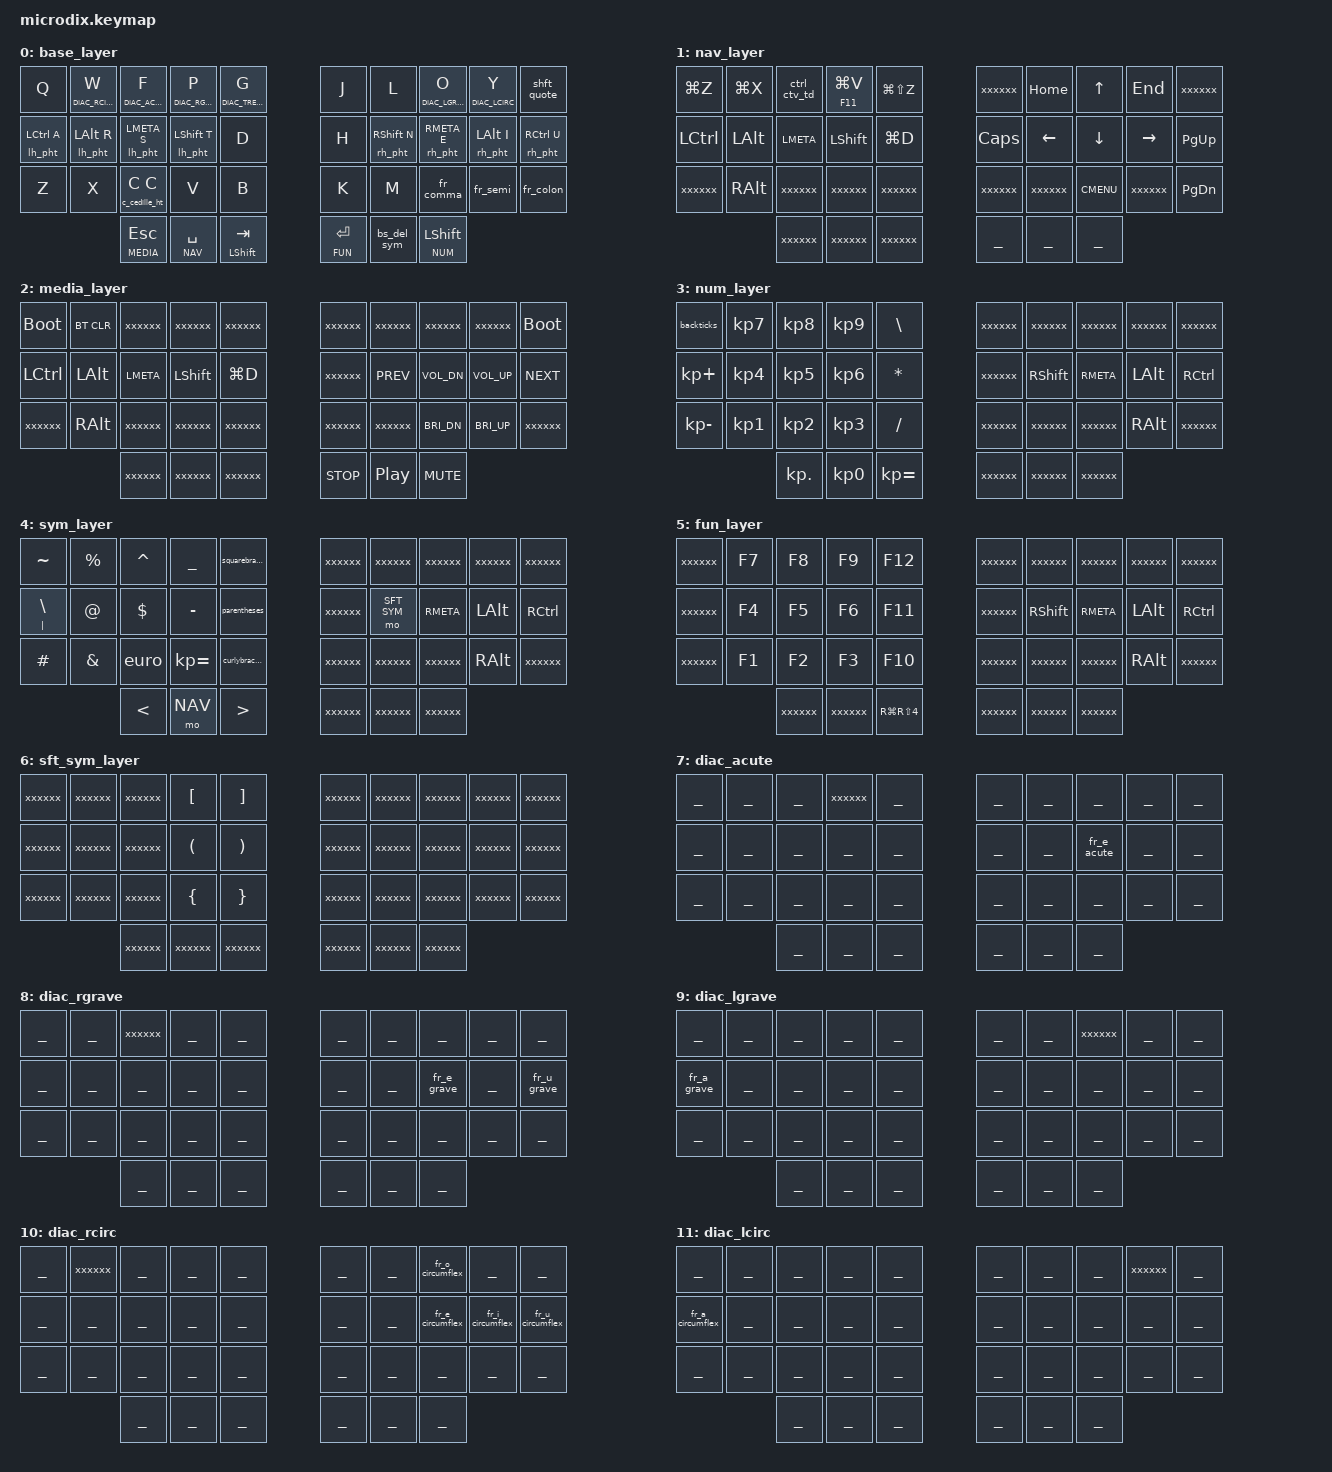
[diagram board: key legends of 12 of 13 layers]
/*
 * Copyright (c) 2020 The ZMK Contributors
 *
 * SPDX-License-Identifier: MIT
 */
#define HOST_OS 2
#include <behaviors.dtsi>
#include <dt-bindings/zmk/keys.h>
#include <dt-bindings/zmk/bt.h>

#include "zmk-helpers/helper.h"
#include "zmk-helpers/key-labels/36.h"
#include "zmk-helpers/unicode-chars/french.dtsi"

#define BASE       0
#define NAV        1
#define MEDIA      2
#define NUM        3
#define SYM        4
#define FUN        5
#define SFT_SYM    6
#define DIAC_ACUTE 7
#define DIAC_RGRAVE 8
#define DIAC_LGRAVE 9
#define DIAC_RCIRC 10
#define DIAC_LCIRC 11
#define DIAC_TREMA 12

#include "include/settings.dtsi"
#include "include/unicode.dtsi"
#include "include/macros.dtsi"
#include "include/combos.dtsi"
#include "include/tap_dance.dtsi"
#include "include/homerow_mod.dtsi"

/* keymap */

ZMK_LAYER(base_layer,
// ╭────────────────────────┬────────────────────────┬────────────────────────┬────────────────────────┬────────────────────────╮    ╭────────────────────────┬────────────────────────┬────────────────────────┬────────────────────────┬────────────────────────╮
    &kp Q                    &lt DIAC_RCIRC W         &lt DIAC_ACUTE F         &lt DIAC_RGRAVE P        &lt DIAC_TREMA G              &kp J                    &kp L                    &lt DIAC_LGRAVE O        &lt DIAC_LCIRC Y         &shft_quote
// ├────────────────────────┼────────────────────────┼────────────────────────┼────────────────────────┼────────────────────────┤    ├────────────────────────┼────────────────────────┼────────────────────────┼────────────────────────┼────────────────────────┤
    &lh_pht LCTRL A          &lh_pht LALT R           &lh_pht LMETA S          &lh_pht LSHFT T          &kp D                         &kp H                    &rh_pht RSHFT N          &rh_pht RMETA E          &rh_pht LALT I           &rh_pht RCTRL U
// ├────────────────────────┼────────────────────────┼────────────────────────┼────────────────────────┼────────────────────────┤    ├────────────────────────┼────────────────────────┼────────────────────────┼────────────────────────┼────────────────────────┤
    &kp Z                    &kp X                    &c_cedille_ht C C        &kp V                    &kp B                         &kp K                    &kp M                    &fr_comma                &fr_semi                 &fr_colon
// ╰────────────────────────┴────────────────────────┴────────────────────────┴────────────────────────┼────────────────────────┤    ├────────────────────────┼────────────────────────┼────────────────────────┼────────────────────────┼────────────────────────╯
                                                      &lt MEDIA ESC            &lt NAV SPACE            &mt LSHFT TAB                 &lt FUN ENTER            &bs_del_sym              &lt NUM LSHFT
//                                                   ╰────────────────────────┴────────────────────────┴────────────────────────╯    ╰────────────────────────┴────────────────────────┴────────────────────────╯
)
ZMK_LAYER(nav_layer,
// ╭────────────────────────┬────────────────────────┬────────────────────────┬────────────────────────┬────────────────────────╮    ╭────────────────────────┬────────────────────────┬────────────────────────┬────────────────────────┬────────────────────────╮
    &kp LG(Z)                &kp LG(X)                &ctrl_ctv_td             &mt F11 LG(V)            &kp LG(LS(Z))                 xxxxxx                   &kp HOME                 &kp UP_ARROW             &kp END                  xxxxxx
// ├────────────────────────┼────────────────────────┼────────────────────────┼────────────────────────┼────────────────────────┤    ├────────────────────────┼────────────────────────┼────────────────────────┼────────────────────────┼────────────────────────┤
    &kp LCTRL                &kp LALT                 &kp LMETA                &kp LSHFT                &kp LG(D)                     &kp CAPSLOCK             &kp LEFT_ARROW           &kp DOWN_ARROW           &kp RIGHT_ARROW          &kp PG_UP
// ├────────────────────────┼────────────────────────┼────────────────────────┼────────────────────────┼────────────────────────┤    ├────────────────────────┼────────────────────────┼────────────────────────┼────────────────────────┼────────────────────────┤
    xxxxxx                   &kp RALT                 xxxxxx                   xxxxxx                   xxxxxx                        xxxxxx                   xxxxxx                   &kp K_CMENU              xxxxxx                   &kp PG_DN
// ╰────────────────────────┴────────────────────────┴────────────────────────┴────────────────────────┼────────────────────────┤    ├────────────────────────┼────────────────────────┼────────────────────────┼────────────────────────┼────────────────────────╯
                                                      xxxxxx                   xxxxxx                   xxxxxx                        ______                   ______                   ______
//                                                   ╰────────────────────────┴────────────────────────┴────────────────────────╯    ╰────────────────────────┴────────────────────────┴────────────────────────╯
)
ZMK_LAYER(media_layer,
// ╭────────────────────────┬────────────────────────┬────────────────────────┬────────────────────────┬────────────────────────╮    ╭────────────────────────┬────────────────────────┬────────────────────────┬────────────────────────┬────────────────────────╮
    &bootloader              &bt BT_CLR               xxxxxx                   xxxxxx                   xxxxxx                        xxxxxx                   xxxxxx                   xxxxxx                   xxxxxx                   &bootloader
// ├────────────────────────┼────────────────────────┼────────────────────────┼────────────────────────┼────────────────────────┤    ├────────────────────────┼────────────────────────┼────────────────────────┼────────────────────────┼────────────────────────┤
    &kp LCTRL                &kp LALT                 &kp LMETA                &kp LSHFT                &kp LG(D)                     xxxxxx                   &kp C_PREV               &kp C_VOL_DN             &kp C_VOL_UP             &kp C_NEXT
// ├────────────────────────┼────────────────────────┼────────────────────────┼────────────────────────┼────────────────────────┤    ├────────────────────────┼────────────────────────┼────────────────────────┼────────────────────────┼────────────────────────┤
    xxxxxx                   &kp RALT                 xxxxxx                   xxxxxx                   xxxxxx                        xxxxxx                   xxxxxx                   &kp C_BRI_DN             &kp C_BRI_UP             xxxxxx
// ╰────────────────────────┴────────────────────────┴────────────────────────┴────────────────────────┼────────────────────────┤    ├────────────────────────┬────────────────────────┬────────────────────────┬────────────────────────┬────────────────────────╯
                                                      xxxxxx                   xxxxxx                   xxxxxx                        &kp C_STOP               &kp C_PP                 &kp C_MUTE
//                                                   ╰────────────────────────┴────────────────────────┴────────────────────────╯    ╰────────────────────────┴────────────────────────┴────────────────────────╯
)
ZMK_LAYER(num_layer,
// ╭────────────────────────┬────────────────────────┬────────────────────────┬────────────────────────┬────────────────────────╮    ╭────────────────────────┬────────────────────────┬────────────────────────┬────────────────────────┬────────────────────────╮
    &backticks              &kp KP_N7                 &kp KP_N8                &kp KP_N9                &kp BSLH                      xxxxxx                   xxxxxx                   xxxxxx                   xxxxxx                   xxxxxx
// ├────────────────────────┼────────────────────────┼────────────────────────┼────────────────────────┼────────────────────────┤    ├────────────────────────┼────────────────────────┼────────────────────────┼────────────────────────┼────────────────────────┤
    &kp KP_PLUS              &kp KP_N4                &kp KP_N5                &kp KP_N6                &kp ASTRK                     xxxxxx                   &kp RSHFT                &kp RMETA                &kp LALT                 &kp RCTRL
// ├────────────────────────┼────────────────────────┼────────────────────────┼────────────────────────┼────────────────────────┤    ├────────────────────────┼────────────────────────┼────────────────────────┼────────────────────────┼────────────────────────┤
    &kp KP_MINUS             &kp KP_N1                &kp KP_N2                &kp KP_N3                &kp SLASH                     xxxxxx                   xxxxxx                   xxxxxx                   &kp RALT                 xxxxxx
// ╰────────────────────────┴────────────────────────┴────────────────────────┴────────────────────────┼────────────────────────┤    ├────────────────────────┬────────────────────────┬────────────────────────┬────────────────────────┬────────────────────────╯
                                                      &kp KP_DOT               &kp KP_N0                &kp KP_EQUAL                  xxxxxx                   xxxxxx                   xxxxxx
//                                                   ╰────────────────────────┴────────────────────────┴────────────────────────╯    ╰────────────────────────┴────────────────────────┴────────────────────────╯
)
ZMK_LAYER(sym_layer,
 // ╭────────────────────────┬────────────────────────┬────────────────────────┬────────────────────────┬────────────────────────╮    ╭────────────────────────┬────────────────────────┬────────────────────────┬────────────────────────┬────────────────────────╮
     &kp TILDE                &kp PERCENT              &kp CARET                &kp UNDER                &squarebrackets               xxxxxx                   xxxxxx                   xxxxxx                   xxxxxx                   xxxxxx
 // ├────────────────────────┼────────────────────────┼────────────────────────┼────────────────────────┼────────────────────────┤    ├────────────────────────┼────────────────────────┼────────────────────────┼────────────────────────┼────────────────────────┤
     &mt PIPE BACKSLASH       &kp AT_SIGN              &kp DLLR                 &kp MINUS                &parentheses                  xxxxxx                   &mo SFT_SYM              &kp RMETA                &kp LALT                 &kp RCTRL
 // ├────────────────────────┼────────────────────────┼────────────────────────┼────────────────────────┼────────────────────────┤    ├────────────────────────┼────────────────────────┼────────────────────────┼────────────────────────┼────────────────────────┤
     &kp HASH                 &kp AMPS                 &euro                    &kp KP_EQUAL             &curlybrackets                xxxxxx                   xxxxxx                   xxxxxx                   &kp RALT                 xxxxxx
 // ╰────────────────────────┴────────────────────────┴────────────────────────┴────────────────────────┼────────────────────────┤    ├────────────────────────┬────────────────────────┬────────────────────────┬────────────────────────┬────────────────────────╯
                                                       &kp LT                   &mo NAV                  &kp GT                        xxxxxx                   xxxxxx                   xxxxxx
 //                                                   ╰────────────────────────┴────────────────────────┴────────────────────────╯    ╰────────────────────────┴────────────────────────┴────────────────────────╯
 )
ZMK_LAYER(fun_layer,
// ╭────────────────────────┬────────────────────────┬────────────────────────┬────────────────────────┬────────────────────────╮    ╭────────────────────────┬────────────────────────┬────────────────────────┬────────────────────────┬────────────────────────╮
    xxxxxx                   &kp F7                   &kp F8                   &kp F9                   &kp F12                       xxxxxx                   xxxxxx                   xxxxxx                   xxxxxx                   xxxxxx
// ├────────────────────────┼────────────────────────┼────────────────────────┼────────────────────────┼────────────────────────┤    ├────────────────────────┼────────────────────────┼────────────────────────┼────────────────────────┼────────────────────────┤
    xxxxxx                   &kp F4                   &kp F5                   &kp F6                   &kp F11                       xxxxxx                   &kp RSHFT                &kp RMETA                &kp LALT                 &kp RCTRL
// ├────────────────────────┼────────────────────────┼────────────────────────┼────────────────────────┼────────────────────────┤    ├────────────────────────┼────────────────────────┼────────────────────────┼────────────────────────┼────────────────────────┤
    xxxxxx                   &kp F1                   &kp F2                   &kp F3                   &kp F10                       xxxxxx                   xxxxxx                   xxxxxx                   &kp RALT                 xxxxxx
// ╰────────────────────────┴────────────────────────┴────────────────────────┴────────────────────────┼────────────────────────┤    ├────────────────────────┬────────────────────────┬────────────────────────┬────────────────────────┬────────────────────────╯
                                                      xxxxxx                   xxxxxx                   &kp RG(RS(N4))                xxxxxx                   xxxxxx                   xxxxxx
//                                                   ╰────────────────────────┴────────────────────────┴────────────────────────╯    ╰────────────────────────┴────────────────────────┴────────────────────────╯
)
ZMK_LAYER(sft_sym_layer,
// ╭────────────────────────┬────────────────────────┬────────────────────────┬────────────────────────┬────────────────────────╮    ╭────────────────────────┬────────────────────────┬────────────────────────┬────────────────────────┬────────────────────────╮
    xxxxxx                   xxxxxx                   xxxxxx                   &kp LBKT                 &kp RBKT                      xxxxxx                   xxxxxx                   xxxxxx                   xxxxxx                   xxxxxx
// ├────────────────────────┼────────────────────────┼────────────────────────┼────────────────────────┼────────────────────────┤    ├────────────────────────┼────────────────────────┼────────────────────────┼────────────────────────┼────────────────────────┤
    xxxxxx                   xxxxxx                   xxxxxx                   &kp LPAR                 &kp RPAR                      xxxxxx                   xxxxxx                   xxxxxx                   xxxxxx                   xxxxxx
// ├────────────────────────┼────────────────────────┼────────────────────────┼────────────────────────┼────────────────────────┤    ├────────────────────────┼────────────────────────┼────────────────────────┼────────────────────────┼────────────────────────┤
    xxxxxx                   xxxxxx                   xxxxxx                   &kp LBRC                 &kp RBRC                      xxxxxx                   xxxxxx                   xxxxxx                   xxxxxx                   xxxxxx
// ╰────────────────────────┴────────────────────────┴────────────────────────┴────────────────────────┼────────────────────────┤    ├────────────────────────┬────────────────────────┬────────────────────────┬────────────────────────┬────────────────────────╯
                                                      xxxxxx                   xxxxxx                   xxxxxx                        xxxxxx                   xxxxxx                   xxxxxx
//                                                   ╰────────────────────────┴────────────────────────┴────────────────────────╯    ╰────────────────────────┴────────────────────────┴────────────────────────╯
)
ZMK_LAYER(diac_acute,
// ╭────────────────────────┬────────────────────────┬────────────────────────┬────────────────────────┬────────────────────────╮    ╭────────────────────────┬────────────────────────┬────────────────────────┬────────────────────────┬────────────────────────╮
    ______                   ______                   ______                   xxxxxx                   ______                        ______                   ______                   ______                   ______                   ______
// ├────────────────────────┼────────────────────────┼────────────────────────┼────────────────────────┼────────────────────────┤    ├────────────────────────┼────────────────────────┼────────────────────────┼────────────────────────┼────────────────────────┤
    ______                   ______                   ______                   ______                   ______                        ______                   ______                   &fr_e_acute              ______                   ______
// ├────────────────────────┼────────────────────────┼────────────────────────┼────────────────────────┼────────────────────────┤    ├────────────────────────┼────────────────────────┼────────────────────────┼────────────────────────┼────────────────────────┤
    ______                   ______                   ______                   ______                   ______                        ______                   ______                   ______                   ______                   ______
// ╰────────────────────────┴────────────────────────┴────────────────────────┴────────────────────────┼────────────────────────┤    ├────────────────────────┬────────────────────────┬────────────────────────┬────────────────────────┬────────────────────────╯
                                                      ______                   ______                   ______                        ______                   ______                   ______
//                                                   ╰────────────────────────┴────────────────────────┴────────────────────────╯    ╰────────────────────────┴────────────────────────┴────────────────────────╯
)
ZMK_LAYER(diac_rgrave,
 // ╭────────────────────────┬────────────────────────┬────────────────────────┬────────────────────────┬────────────────────────╮    ╭────────────────────────┬────────────────────────┬────────────────────────┬────────────────────────┬────────────────────────╮
     ______                   ______                   xxxxxx                   ______                   ______                        ______                   ______                   ______                   ______                   ______
 // ├────────────────────────┼────────────────────────┼────────────────────────┼────────────────────────┼────────────────────────┤    ├────────────────────────┼────────────────────────┼────────────────────────┼────────────────────────┼────────────────────────┤
     ______                   ______                   ______                   ______                   ______                        ______                   ______                   &fr_e_grave              ______                   &fr_u_grave
 // ├────────────────────────┼────────────────────────┼────────────────────────┼────────────────────────┼────────────────────────┤    ├────────────────────────┼────────────────────────┼────────────────────────┼────────────────────────┼────────────────────────┤
     ______                   ______                   ______                   ______                   ______                        ______                   ______                   ______                   ______                   ______
 // ╰────────────────────────┴────────────────────────┴────────────────────────┴────────────────────────┼────────────────────────┤    ├────────────────────────┬────────────────────────┬────────────────────────┬────────────────────────┬────────────────────────╯
                                                       ______                   ______                   ______                        ______                   ______                   ______
 //                                                   ╰────────────────────────┴────────────────────────┴────────────────────────╯    ╰────────────────────────┴────────────────────────┴────────────────────────╯
 )
ZMK_LAYER(diac_lgrave,
// ╭────────────────────────┬────────────────────────┬────────────────────────┬────────────────────────┬────────────────────────╮    ╭────────────────────────┬────────────────────────┬────────────────────────┬────────────────────────┬────────────────────────╮
    ______                   ______                   ______                   ______                   ______                        ______                   ______                   xxxxxx                   ______                   ______
// ├────────────────────────┼────────────────────────┼────────────────────────┼────────────────────────┼────────────────────────┤    ├────────────────────────┼────────────────────────┼────────────────────────┼────────────────────────┼────────────────────────┤
    &fr_a_grave              ______                   ______                   ______                   ______                        ______                   ______                   ______                   ______                   ______
// ├────────────────────────┼────────────────────────┼────────────────────────┼────────────────────────┼────────────────────────┤    ├────────────────────────┼────────────────────────┼────────────────────────┼────────────────────────┼────────────────────────┤
    ______                   ______                   ______                   ______                   ______                        ______                   ______                   ______                   ______                   ______
// ╰────────────────────────┴────────────────────────┴────────────────────────┴────────────────────────┼────────────────────────┤    ├────────────────────────┬────────────────────────┬────────────────────────┬────────────────────────┬────────────────────────╯
                                                      ______                   ______                   ______                        ______                   ______                   ______
//                                                   ╰────────────────────────┴────────────────────────┴────────────────────────╯    ╰────────────────────────┴────────────────────────┴────────────────────────╯
)
ZMK_LAYER(diac_rcirc,
// ╭────────────────────────┬────────────────────────┬────────────────────────┬────────────────────────┬────────────────────────╮    ╭────────────────────────┬────────────────────────┬────────────────────────┬────────────────────────┬────────────────────────╮
    ______                   xxxxxx                   ______                   ______                   ______                        ______                   ______                   &fr_o_circumflex         ______                   ______
// ├────────────────────────┼────────────────────────┼────────────────────────┼────────────────────────┼────────────────────────┤    ├────────────────────────┼────────────────────────┼────────────────────────┼────────────────────────┼────────────────────────┤
    ______                   ______                   ______                   ______                   ______                        ______                   ______                   &fr_e_circumflex         &fr_i_circumflex         &fr_u_circumflex
// ├────────────────────────┼────────────────────────┼────────────────────────┼────────────────────────┼────────────────────────┤    ├────────────────────────┼────────────────────────┼────────────────────────┼────────────────────────┼────────────────────────┤
    ______                   ______                   ______                   ______                   ______                        ______                   ______                   ______                   ______                   ______
// ╰────────────────────────┴────────────────────────┴────────────────────────┴────────────────────────┼────────────────────────┤    ├────────────────────────┬────────────────────────┬────────────────────────┬────────────────────────┬────────────────────────╯
                                                      ______                   ______                   ______                        ______                   ______                   ______
//                                                   ╰────────────────────────┴────────────────────────┴────────────────────────╯    ╰────────────────────────┴────────────────────────┴────────────────────────╯
)
ZMK_LAYER(diac_lcirc,
// ╭────────────────────────┬────────────────────────┬────────────────────────┬────────────────────────┬────────────────────────╮    ╭────────────────────────┬────────────────────────┬────────────────────────┬────────────────────────┬────────────────────────╮
    ______                   ______                   ______                   ______                   ______                        ______                   ______                   ______                   xxxxxx                   ______
// ├────────────────────────┼────────────────────────┼────────────────────────┼────────────────────────┼────────────────────────┤    ├────────────────────────┼────────────────────────┼────────────────────────┼────────────────────────┼────────────────────────┤
    &fr_a_circumflex         ______                   ______                   ______                   ______                        ______                   ______                   ______                   ______                   ______
// ├────────────────────────┼────────────────────────┼────────────────────────┼────────────────────────┼────────────────────────┤    ├────────────────────────┼────────────────────────┼────────────────────────┼────────────────────────┼────────────────────────┤
    ______                   ______                   ______                   ______                   ______                        ______                   ______                   ______                   ______                   ______
// ╰────────────────────────┴────────────────────────┴────────────────────────┴────────────────────────┼────────────────────────┤    ├────────────────────────┬────────────────────────┬────────────────────────┬────────────────────────┬────────────────────────╯
                                                      ______                   ______                   ______                        ______                   ______                   ______
//                                                   ╰────────────────────────┴────────────────────────┴────────────────────────╯    ╰────────────────────────┴────────────────────────┴────────────────────────╯
)
ZMK_LAYER(diac_trema,
// ╭────────────────────────┬────────────────────────┬────────────────────────┬────────────────────────┬────────────────────────╮    ╭────────────────────────┬────────────────────────┬────────────────────────┬────────────────────────┬────────────────────────╮
    ______                   ______                   ______                   ______                   xxxxxx                        ______                   ______                   ______                   &fr_y_diaeresis          ______
// ├────────────────────────┼────────────────────────┼────────────────────────┼────────────────────────┼────────────────────────┤    ├────────────────────────┼────────────────────────┼────────────────────────┼────────────────────────┼────────────────────────┤
    ______                   ______                   ______                   ______                   ______                        ______                   ______                   &fr_e_diaeresis          &fr_i_diaeresis          &fr_u_diaeresis
// ├────────────────────────┼────────────────────────┼────────────────────────┼────────────────────────┼────────────────────────┤    ├────────────────────────┼────────────────────────┼────────────────────────┼────────────────────────┼────────────────────────┤
    ______                   ______                   ______                   ______                   ______                        ______                   ______                   ______                   ______                   ______
// ╰────────────────────────┴────────────────────────┴────────────────────────┴────────────────────────┼────────────────────────┤    ├────────────────────────┬────────────────────────┬────────────────────────┬────────────────────────┬────────────────────────╯
                                                      ______                   ______                   ______                        ______                   ______                   ______
//                                                   ╰────────────────────────┴────────────────────────┴────────────────────────╯    ╰────────────────────────┴────────────────────────┴────────────────────────╯
)

